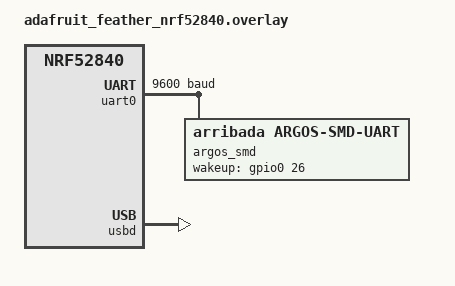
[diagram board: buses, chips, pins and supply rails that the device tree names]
#include <zephyr/dt-bindings/gpio/gpio.h>

/ {
	chosen {
		zephyr,console = &cdc_acm_uart;
		/delete-property/ zephyr,shell-uart;
		/delete-property/ zephyr,uart-mcumgr;
		/delete-property/ zephyr,bt-mon-uart;
		/delete-property/ zephyr,bt-c2h-uart;
	};
};

&uart0 {
	status = "okay";
	current-speed = <9600>;

	argos_smd {
		compatible = "arribada,argos-smd-uart";

		/*
		 * Wake-up line for the STM32WL55 low-power modes (STANDBY/SHUTDOWN).
		 *
		 * In SHUTDOWN the STM32WL powers down its whole VCORE domain: the
		 * UART is dead and the module can ONLY be woken by a rising edge on
		 * WKUP3 = STM32 PB3, by NRST, or by its internal RTC. The Kineis
		 * firmware arms WKUP3/PB3 on a rising edge, so the host drives this
		 * pin HIGH to wake the module.
		 *
		 * Required wiring:  Feather D9 (P0.26)  ->  STM32 PB3 / WKUP3
		 *
		 * The LPM test calls argos_smd_wakeup_enable() (drives this pin HIGH)
		 * to wake and argos_smd_wakeup_disable() (LOW) to let it sleep.
		 */
		wakeup-gpios = <&gpio0 26 GPIO_ACTIVE_HIGH>;
	};
};

zephyr_udc0: &usbd {
	compatible = "nordic,nrf-usbd";
	status = "okay";
	cdc_acm_uart: cdc_acm_uart0 {
		compatible = "zephyr,cdc-acm-uart";
		label = "CDC_ACM";
	};
};
